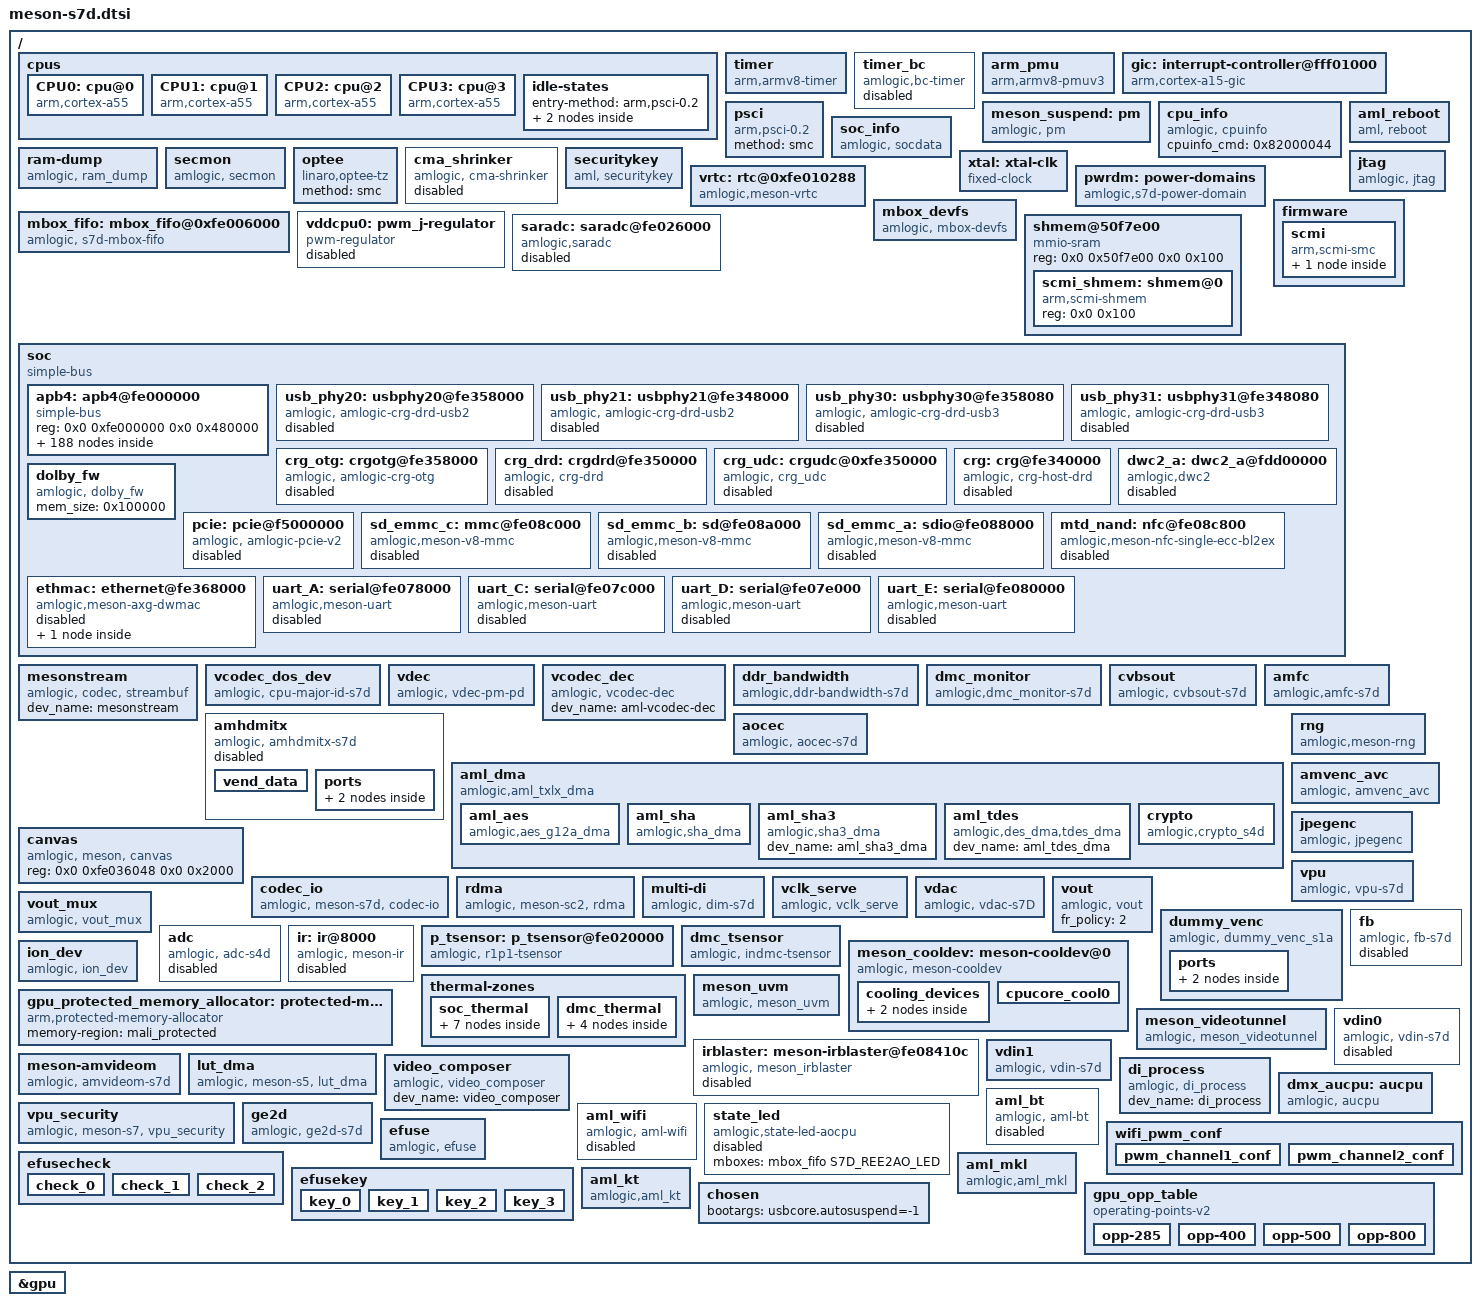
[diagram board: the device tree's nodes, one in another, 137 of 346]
// SPDX-License-Identifier: (GPL-2.0+ OR MIT)
/*
 * Copyright (c) 2019 Amlogic, Inc. All rights reserved.
 */

#include <dt-bindings/clock/s7d-clkc.h>
#include <dt-bindings/clock/s7d-scmi-clkc.h>
#include <dt-bindings/clock/g12a-aoclkc.h>
#include <dt-bindings/interrupt-controller/irq.h>
#include <dt-bindings/interrupt-controller/arm-gic.h>
#include <dt-bindings/power/s7d-pd.h>
#include <dt-bindings/gpio/gpio.h>
#include <dt-bindings/gpio/meson-s7d-gpio.h>
#include <dt-bindings/reset/amlogic,meson-s7d-reset.h>
#include <dt-bindings/pwm/pwm.h>
#include <dt-bindings/pwm/meson.h>
#include <dt-bindings/input/input.h>
#include <dt-bindings/input/meson_ir.h>
#include <dt-bindings/mailbox/amlogic,mbox.h>
#include <dt-bindings/mailbox/s7d-mbox.h>
#include <dt-bindings/iio/adc/amlogic-saradc.h>
#include "meson-ir-map.dtsi"
#include "meson-valhall.dtsi"

/ {
	cpus:cpus {
		#address-cells = <2>;
		#size-cells = <0>;

		CPU0:cpu@0 {
			device_type = "cpu";
			compatible = "arm,cortex-a55","arm,armv8";
			reg = <0x0 0x0>;
			enable-method = "psci";
			cpu-idle-states = <&CPU_SLEEP_0 &SYSTEM_SLEEP_0>;
			dynamic-power-coefficient = <230>;
			#cooling-cells = <2>;
		};

		CPU1:cpu@1 {
			device_type = "cpu";
			compatible = "arm,cortex-a55","arm,armv8";
			reg = <0x0 0x100>;
			enable-method = "psci";
			cpu-idle-states = <&CPU_SLEEP_0 &SYSTEM_SLEEP_0>;
			dynamic-power-coefficient = <230>;
			#cooling-cells = <2>;
		};

		CPU2:cpu@2 {
			device_type = "cpu";
			compatible = "arm,cortex-a55","arm,armv8";
			reg = <0x0 0x200>;
			enable-method = "psci";
			cpu-idle-states = <&CPU_SLEEP_0 &SYSTEM_SLEEP_0>;
			dynamic-power-coefficient = <230>;
			#cooling-cells = <2>;
		};

		CPU3:cpu@3 {
			device_type = "cpu";
			compatible = "arm,cortex-a55","arm,armv8";
			reg = <0x0 0x300>;
			enable-method = "psci";
			cpu-idle-states = <&CPU_SLEEP_0 &SYSTEM_SLEEP_0>;
			dynamic-power-coefficient = <230>;
			#cooling-cells = <2>;
		};

		idle-states {
			entry-method = "arm,psci-0.2";
			CPU_SLEEP_0: cpu-sleep-0 {
					compatible = "arm,idle-state";
					arm,psci-suspend-param = <0x0010000>;
					local-timer-stop;
					entry-latency-us = <1444>;
					exit-latency-us = <675>;
					min-residency-us = <2638>;
			};
			SYSTEM_SLEEP_0: system-sleep-0 {
					compatible = "arm,idle-state";
					arm,psci-suspend-param = <0x0000000>;
					entry-latency-us = <0x3fffffff>;
					exit-latency-us = <0x40000000>;
					min-residency-us = <0xffffffff>;
			};
		};
	};

	timer {
		compatible = "arm,armv8-timer";
		interrupts = <GIC_PPI 13 0xff08>,
				<GIC_PPI 14 0xff08>,
				<GIC_PPI 11 0xff08>,
				<GIC_PPI 10 0xff08>;
	};

	timer_bc {
		compatible = "amlogic,bc-timer";
		status = "disabled";
		reg= <0x0 0xfe0100D8 0x0 0x4 0x0 0xfe0100DC 0x0 0x4>;
		timer_name = "Meson TimerD";
		clockevent-rating=<300>;
		clockevent-shift=<20>;
		clockevent-features=<0x23>;
		interrupts = <0 3 1>;
		bit_enable=<7>;
		bit_mode=<6>;
		bit_resolution=<0>;
		resolution_1us=<1>;
		min_delta_ns=<10>;
	};

	arm_pmu {
		compatible = "arm,armv8-pmuv3";
		private-interrupts;
		/* clusterb-enabled; */
		interrupts = <GIC_SPI 235 IRQ_TYPE_LEVEL_HIGH>,
				<GIC_SPI 236 IRQ_TYPE_LEVEL_HIGH>,
				<GIC_SPI 237 IRQ_TYPE_LEVEL_HIGH>,
				<GIC_SPI 238 IRQ_TYPE_LEVEL_HIGH>;
	};

	gic: interrupt-controller@fff01000 {
		compatible = "arm,cortex-a15-gic", "arm,cortex-a9-gic";
		#interrupt-cells = <3>;
		#address-cells = <0>;
		interrupt-controller;
		reg = <0x0 0xfff01000 0 0x1000>,
		      <0x0 0xfff02000 0 0x0100>;
		interrupts = <GIC_PPI 9 0xf04>;
	};

	psci {
		compatible = "arm,psci-0.2";
		method = "smc";
	};

	meson_suspend:pm {
		compatible = "amlogic, pm";
		status = "okay";
		device_name = "aml_pm";
		extend_resume_reason;
		reg = <0x0 0xfe010288 0x0 0x4>, /*SYSCTRL_STATUS_REG2*/
			<0x0 0xfe0102dc 0x0 0x4>; /*SYSCTRL_STICKY_REG7*/
	};

	cpu_info {
		compatible = "amlogic, cpuinfo";
		status = "okay";
		cpuinfo_cmd = <0x82000044>;
	};

	soc_info {
		compatible = "amlogic, socdata";
		reg =	<0x0 0xfe010000 0x0 0xc>,
			<0x0 0xfe010180 0x0 0x4>;
		read_nocsdata_cmd =<0x82000039>;
		write_nocsdata_cmd=<0x82000038>;
		auth_reg_ops_cmd=<0x820000f0>;
	};

	aml_reboot {
		compatible = "aml, reboot";
		sys_reset = <0x84000009>;
		sys_poweroff = <0x84000008>;
		dis_nb_cpus_in_shutdown;
		extend_reboot_reason; /* Support up to 128 reboot reasons*/
		reg = <0x0 0xfe01037c 0x0 0x4>; /* SEC_AO_SEC_SD_CFG15 */
		status = "okay";
	};

	ram-dump {
		compatible = "amlogic, ram_dump";
		status = "okay";
		reg = <0x0 0xFE0102D8 0x0 4>;
		reg-names = "SYSCTRL_STICKY_REG6";
		store_device = "data";
	};

	secmon:secmon {
		compatible = "amlogic, secmon";
		memory-region = <&secmon_reserved>;
		in_base_func = <0x82000020>;
		out_base_func = <0x82000021>;
		inout_size_func = <0x8200002a>;
		reserve_mem_size = <0x03300000>;
	};

	optee {
		compatible = "linaro,optee-tz";
		method = "smc";
	};

	cma_shrinker: cma_shrinker {
		compatible = "amlogic, cma-shrinker";
		status = "disabled";
		adj  = <0 100 200 250 900 950>;
		free = <8192 12288 16384 24576 28672 32768>;
	};

	securitykey {
		compatible = "aml, securitykey";
		storage_query = <0x82000060>;
		storage_read = <0x82000061>;
		storage_write = <0x82000062>;
		storage_tell = <0x82000063>;
		storage_verify = <0x82000064>;
		storage_status = <0x82000065>;
		storage_list = <0x82000067>;
		storage_remove = <0x82000068>;
		storage_in_func = <0x82000023>;
		storage_out_func = <0x82000024>;
		storage_block_func = <0x82000025>;
		storage_size_func = <0x82000027>;
		storage_set_enctype = <0x8200006A>;
		storage_get_enctype = <0x8200006B>;
		storage_version = <0x8200006C>;
	};

	xtal: xtal-clk {
		compatible = "fixed-clock";
		clock-frequency = <24000000>;
		clock-output-names = "xtal";
		#clock-cells = <0>;
	};

	vrtc: rtc@0xfe010288 {
		compatible = "amlogic,meson-vrtc";
		reg = <0x0 0xfe010288 0x0 0x4>;
		status = "okay";
		mboxes = <&mbox_fifo S7D_REE2AO_VRTC>;
	};

	pwrdm: power-domains {
		compatible = "amlogic,s7d-power-domain";
		#power-domain-cells = <1>;
		status = "okay";
	};

	jtag {
		compatible = "amlogic, jtag";
		status = "okay";
		select = "disable"; /* disable/jtag_a/jtag_b */
		pinctrl-names="jtag_a_pins", "jtag_b_pins";
		pinctrl-0=<&jtag_a_pins>;
		pinctrl-1=<&jtag_b_pins>;
	};

	mbox_fifo: mbox_fifo@0xfe006000 {
		status = "okay";
		compatible = "amlogic, s7d-mbox-fifo";
		reg = <0x0 0xfe006000 0x0 0x800>,  /* mbox wr fifo */
		      <0x0 0xfe006800 0x0 0x800>,  /* mbox rd fifo */
		      <0x0 0xfe0070c0 0x0 0x40>,   /* mbox set reg */
		      <0x0 0xfe007100 0x0 0x40>,   /* mbox clr reg */
		      <0x0 0xfe007140 0x0 0x40>,   /* mbox sts reg */
		      <0x0 0xfe007020 0x0 0x40>;   /* mbox irqctrl reg */
		interrupts = <GIC_SPI 248 IRQ_TYPE_EDGE_RISING>;   /* mbox top irq */
		mbox-irqctlr = <0>;
		mbox-nums = <S7D_MBOX_NUMS>;
		mboxids = <S7D_MBOX_AO2REE>,
			  <S7D_MBOX_REE2AO>;
		aocpu_sts_mboxid = <S7D_MBOX_AO2TEE>;
		ree2aocpu_mboxid = <S7D_MBOX_REE2AO>;
		#mbox-cells = <1>;
	};

	mbox_devfs {
		status = "okay";
		compatible = "amlogic, mbox-devfs";
		mbox-nums = <1>;
		mbox-names = "ree2aocpu";
		mboxes = <&mbox_fifo S7D_REE2AO_DEV>;
		mbox-dests = <MAILBOX_AOCPU>;
	};

	vddcpu0: pwm_j-regulator {
		compatible = "pwm-regulator";
		pwms = <&pwm_j MESON_PWM_0 1000 0>;
		regulator-name = "vddcpu0";
		regulator-min-microvolt = <679000>;
		regulator-max-microvolt = <979000>;
		regulator-always-on;
		max-duty-cycle = <1000>;
		amlogic,vsel-step = <3>;
		amlogic,usleep-time = <200>;
		/* Voltage Duty-Cycle */
		voltage-table = <979000 0>,
				<969000 3>,
				<959000 7>,
				<949000 10>,
				<939000 13>,
				<929000 17>,
				<919000 20>,
				<909000 23>,
				<899000 26>,
				<889000 30>,
				<879000 33>,
				<869000 36>,
				<859000 40>,
				<849000 43>,
				<839000 46>,
				<829000 50>,
				<819000 54>,
				<809000 57>,
				<799000 60>,
				<789000 64>,
				<779000 67>,
				<769000 70>,
				<759000 74>,
				<749000 77>,
				<739000 80>,
				<729000 84>,
				<719000 87>,
				<709000 90>,
				<699000 93>,
				<689000 97>,
				<679000 100>;
		status = "disabled";
	};

	saradc: saradc@fe026000 {
		compatible = "amlogic,saradc";
		reg = <0x00 0xfe026000 0x00 0x84>;
		interrupts = <GIC_SPI 181 IRQ_TYPE_EDGE_RISING>;
		clock-names = "src", "core", "gate", "mux";
		clocks = <&xtal>,
			 <&clkc CLKID_SYS_SAR_ADC>,
			 <&clkc CLKID_SAR_ADC>,
			 <&clkc CLKID_SAR_ADC_SEL>;
		#io-channel-cells = <1>;
		amlogic,clock-frequency = <3000000>;
		amlogic,test-channel = <7>;
		amlogic,fifo-data-width = <16>;
		status = "disabled";
	};

	shmem@50f7e00 {
		compatible = "mmio-sram";
		reg = <0x0 0x50f7e00 0x0 0x100>;
		#address-cells = <1>;
		#size-cells = <1>;
		ranges = <0 0x0 0x50f7e00 0x100>;

		scmi_shmem: shmem@0 {
			compatible = "arm,scmi-shmem";
			reg = <0x0 0x100>;
		};
	};

	firmware {
		scmi: scmi {
			compatible = "arm,scmi-smc";
			arm,smc-id = <0x820000C1>;
			shmem = <&scmi_shmem>;
			#address-cells = <1>;
			#size-cells = <0>;

			scmi_clk: protocol@14 {
				reg = <0x14>;
				#clock-cells = <1>;
			};
		};
	};

	soc {
		compatible = "simple-bus";
		#address-cells = <2>;
		#size-cells = <2>;
		ranges;

		apb4: apb4@fe000000 {
			compatible = "simple-bus";
			reg = <0x0 0xfe000000 0x0 0x480000>;
			#address-cells = <2>;
			#size-cells = <2>;
			ranges = <0x0 0x0 0x0 0xfe000000 0x0 0x480000>;

			clkc: clock-controller {
				compatible = "amlogic,s7d-clkc";
				#clock-cells = <1>;
				reg = <0x0 0x0 0x0 0x49c>,
				      <0x0 0x8000 0x0 0x384>;
				reg-names = "basic", "pll";
				clocks = <&xtal>,
					 <&scmi_clk CLKID_SCMI_GP0_PLL_SRC>,
					 <&scmi_clk CLKID_SCMI_HIFI0_PLL_SRC>,
					 <&scmi_clk CLKID_SCMI_ETH_HIFI1_PLL_SRC>,
					 <&scmi_clk CLKID_SCMI_SYS_CLK>,
					 <&scmi_clk CLKID_SCMI_AXI_CLK>,
					 <&scmi_clk CLKID_SCMI_FIXED_PLL>,
					 <&scmi_clk CLKID_SCMI_GP1_PLL>;
				clock-names = "xtal",
					      "gp0_pll_src",
					      "hifi0_pll_src",
					      "hifi1_pll_src",
					      "sys_clk",
					      "axi_clk",
					      "fixed_pll",
					      "gp1_pll";
				status = "okay";
			};

			meson_clk_msr@48000 {
				compatible = "amlogic,meson-s7d-clk-measure";
				reg = <0x0 0x48000 0x0 0x1c>;
			};

			watchdog@2100 {
				compatible = "amlogic,meson-sc2-wdt";
				status = "okay";
				/* 0:userspace, 1:kernel */
				amlogic,feed_watchdog_mode = <1>;
				reg = <0x0 0x2100 0x0 0x10>;
				clocks = <&xtal>;
			};

			periphs_pinctrl: pinctrl@4000 {
				compatible = "amlogic,meson-s7d-periphs-pinctrl";
				#address-cells = <2>;
				#size-cells = <2>;
				ranges;

				gpio: bank@4000 {
					reg = <0x0 0x4000 0x0 0x004c>,
					      <0x0 0x40c0 0x0 0x02cc>;
					reg-names = "mux", "gpio";
					gpio-controller;
					#gpio-cells = <2>;
					gpio-ranges = <&periphs_pinctrl 0 0 84>;
				};
			};

			gpio_intc: interrupt-controller@4080 {
				compatible = "amlogic,meson-s7-gpio-intc",
					     "amlogic,meson-gpio-intc";
				reg = <0x0 0x4080 0x0 0x20>;
				interrupt-controller;
				#interrupt-cells = <2>;
				amlogic,channel-interrupts =
					<10 11 12 13 14 15 16 17 18 19 20 21>;
			};

			spicc0: spi@50000 {
				compatible = "amlogic,meson-a4-spicc-v2";
				reg = <0x0 0x50000 0x0 0x38>;
				interrupts = <GIC_SPI 183 IRQ_TYPE_LEVEL_HIGH>;
				clocks = <&clkc CLKID_SYS_SPICC0>,
					 <&clkc CLKID_SPICC>;
				clock-names = "sys", "spi";
				assigned-clocks = <&clkc CLKID_SPICC>;
				assigned-clock-rates = <500000000>;
				#address-cells = <1>;
				#size-cells = <0>;
				status = "disabled";
			};

			spifc: spi@56000 {
				compatible = "amlogic,meson-spifc";
				status = "disabled";
				reg = <0x0 0x56000 0x0 0x80>;
				//clock-names = "default";
				//clocks = <&clkc CLKID_SPIFC>;
				pinctrl-names = "default";
				pinctrl-0 = <&spifc_pins>;
				#address-cells = <1>;
				#size-cells = <0>;
				spi-nor@0 {
					compatible = "jedec,spi-nor";
					status = "disabled";
					reg = <0>;
					spi-max-frequency = <16000000>;
				};
			};

			pwm_a: pwm@58000 {
				compatible = "amlogic,meson-even-pwm";
				reg = <0x0 0x58000 0x0 0x24>,
					  <0x0 0x180 0x0 0x4>;
				#pwm-cells = <3>;
				clocks = <&clkc CLKID_PWM_A_SEL>;
				clock-names = "clkin0";
				status = "disabled";
			};

			pwm_b: pwm@58200 {
				compatible = "amlogic,meson-odd-pwm";
				reg = <0x0 0x58200 0x0 0x24>,
					  <0x0 0x180 0x0 0x4>;
				#pwm-cells = <3>;
				clocks = <&clkc CLKID_PWM_B_SEL>;
				clock-names = "clkin0";
				status = "disabled";
			};

			pwm_c: pwm@58400 {
				compatible = "amlogic,meson-even-pwm";
				reg = <0x0 0x58400 0x0 0x24>,
					  <0x0 0x184 0x0 0x4>;
				#pwm-cells = <3>;
				clocks = <&clkc CLKID_PWM_C_SEL>;
				clock-names = "clkin0";
				status = "disabled";
			};

			pwm_d: pwm@58600 {
				compatible = "amlogic,meson-odd-pwm";
				reg = <0x0 0x58600 0x0 0x24>,
					  <0x0 0x184 0x0 0x4>;
				#pwm-cells = <3>;
				clocks = <&clkc CLKID_PWM_D_SEL>;
				clock-names = "clkin0";
				status = "disabled";
			};

			pwm_e: pwm@58800 {
				compatible = "amlogic,meson-even-pwm";
				reg = <0x0 0x58800 0x0 0x24>,
					  <0x0 0x188 0x0 0x4>;
				#pwm-cells = <3>;
				clocks = <&clkc CLKID_PWM_E_SEL>;
				clock-names = "clkin0";
				status = "disabled";
			};

			pwm_f: pwm@58a00 {
				compatible = "amlogic,meson-odd-pwm";
				reg = <0x0 0x58a00 0x0 0x24>,
					  <0x0 0x188 0x0 0x4>;
				#pwm-cells = <3>;
				clocks = <&clkc CLKID_PWM_F_SEL>;
				clock-names = "clkin0";
				status = "disabled";
			};

			pwm_g: pwm@58c00 {
				compatible = "amlogic,meson-even-pwm";
				reg = <0x0 0x58c00 0x0 0x24>,
					  <0x0 0x18c 0x0 0x4>;
				#pwm-cells = <3>;
				clocks = <&clkc CLKID_PWM_G_SEL>;
				clock-names = "clkin0";
				status = "disabled";
			};

			pwm_h: pwm@58e00 {
				compatible = "amlogic,meson-odd-pwm";
				reg = <0x0 0x58e00 0x0 0x24>,
					  <0x0 0x18c 0x0 0x4>;
				#pwm-cells = <3>;
				clocks = <&clkc CLKID_PWM_H_SEL>;
				clock-names = "clkin0";
				status = "disabled";
			};

			pwm_i: pwm@59000 {
				compatible = "amlogic,meson-even-pwm";
				reg = <0x0 0x59000 0x0 0x24>,
					  <0x0 0x190 0x0 0x4>;
				#pwm-cells = <3>;
				clocks = <&clkc CLKID_PWM_I_SEL>;
				clock-names = "clkin0";
				status = "disabled";
			};

			pwm_j: pwm@59200 {
				compatible = "amlogic,meson-pwm-tee";
				reg = <0x0 0x59200 0x0 0x24>;
				#pwm-cells = <3>;
				clocks = <&clkc CLKID_PWM_J>;
				clock-names = "clkin0";
				tee_id = <9>;
				status = "okay";
			};

			i2c0: i2c@66000 {
				compatible = "amlogic,meson-i2c";
				reg = <0x0 0x66000 0x0 0x48>;
				interrupts = <GIC_SPI 160 IRQ_TYPE_EDGE_RISING>;
				#address-cells = <1>;
				#size-cells = <0>;
				clocks = <&clkc CLKID_SYS_I2C_M_A>;
				status = "disabled";
			};

			i2c1: i2c@66400 {
				compatible = "amlogic,meson-i2c";
				reg = <0x0 0x66400 0x0 0x48>;
				interrupts = <GIC_SPI 161 IRQ_TYPE_EDGE_RISING>;
				#address-cells = <1>;
				#size-cells = <0>;
				clocks = <&clkc CLKID_SYS_I2C_M_B>;
				status = "disabled";
			};

			i2c2: i2c@66800 {
				compatible = "amlogic,meson-i2c";
				reg = <0x0 0x66800 0x0 0x48>;
				interrupts = <GIC_SPI 162 IRQ_TYPE_EDGE_RISING>;
				#address-cells = <1>;
				#size-cells = <0>;
				clocks = <&clkc CLKID_SYS_I2C_M_C>;
				status = "disabled";
			};

			i2c3: i2c@66c00 {
				compatible = "amlogic,meson-i2c";
				reg = <0x0 0x66c00 0x0 0x48>;
				interrupts = <GIC_SPI 163 IRQ_TYPE_EDGE_RISING>;
				#address-cells = <1>;
				#size-cells = <0>;
				clocks = <&clkc CLKID_SYS_I2C_M_D>;
				status = "disabled";
			};

			i2c4: i2c@67000 {
				compatible = "amlogic,meson-i2c";
				reg = <0x0 0x67000 0x0 0x48>;
				interrupts = <GIC_SPI 164 IRQ_TYPE_EDGE_RISING>;
				#address-cells = <1>;
				#size-cells = <0>;
				clocks = <&clkc CLKID_SYS_I2C_M_E>;
				status = "disabled";
			};

			uart_B: serial@7a000 {
				compatible = "amlogic,meson-uart";
				reg = <0x0 0x7a000 0x0 0x18>;
				interrupts = <0 169 1>;
				status = "okay";
				clocks = <&xtal>;
				clock-names = "clk_uart";
				xtal_tick_en = <2>;
				fifosize = < 64 >;
				support-sysrq = <1>;  /* 0 not support*/
			};


			eth_phy: mdio-multiplexer@360000 {
				compatible = "amlogic,g12a-mdio-mux";
				reg = <0x0 0x360000 0x0 0xa4>;

				clocks = <&clkc CLKID_SYS_ETHPHY>,
					 <&xtal>,
					 <&clkc CLKID_FCLK_CLK50M>,
					 <&clkc CLKID_ETH_RMII>;
				clock-names = "pclk", "clkin0", "clkin1","ethrmii";
				assigned-clocks = <&clkc CLKID_ETH_RMII>;
				assigned-clock-rates = <50000000>;
				mdio-parent-bus = <&mdio0>;
				#address-cells = <1>;
				#size-cells = <0>;
				enet_type = <5>;
				phy_pll_mode = <3>;
				phy_mode = <5>;
				tx_amp_src = <0xFE010330>;
				led_setting = <0x42>;

				ext_mdio: mdio@0 {
					reg = <0>;
					#address-cells = <1>;
					#size-cells = <0>;
				};

				int_mdio: mdio@1 {
					reg = <1>;
					#address-cells = <1>;
					#size-cells = <0>;

					internal_ephy: ethernet_phy@8 {
						compatible = "ethernet-phy-id0180.3301",
							     "ethernet-phy-ieee802.3-c22";
						interrupts = <GIC_SPI 75 IRQ_TYPE_LEVEL_HIGH>;
						reg = <8>;
						max-speed = <100>;
					};
				};
			};

			reset: reset-controller@2000 {
				compatible = "amlogic,meson-sc2-reset";
				reg = <0x0 0x2000 0x0 0x98>;
				#reset-cells = <1>;
			};
		};

		usb_phy20: usbphy20@fe358000 {
			compatible = "amlogic, amlogic-crg-drd-usb2";
			status = "disable";
			reg = <0x0 0xfe358000 0x0 0x10 /* phy_base */
					0x0 0xfe002000 0x0 0x100 /* reset_base */
					0x0 0xfe35c000 0x0 0x60>; /* phy_cfg_base(s) */
			pll-setting-1 = <0x244a0030>;
			pll-setting-2 = <0x03200022>;
			pll-setting-4 = <0x7e18>;
			pll-setting-5 = <0x7>;
			//dis-thred-enhance = <0x2>;
			pll-version = <3>;
			phy0-reset-level-bit = <8>;
			usb-reset-bit = <5>;
			reset-level = <0x40>;
			usb-phy-trim-reg = <0xfe010330>;
			phy-id = <0>;
			clocks = <&clkc CLKID_SYS_USB>;
			clock-names = "crg_general";
		};

		usb_phy21: usbphy21@fe348000 {
			compatible = "amlogic, amlogic-crg-drd-usb2";
			status = "disable";
			reg = <0x0 0xfe348000 0x0 0x10 /* phy_base */
					0x0 0xfe002000 0x0 0x100 /* reset_base */
					0x0 0xfe34c000 0x0 0x60>; /* phy_cfg_base(s) */
			pll-setting-1 = <0x244a0030>;
			pll-setting-2 = <0x03200022>;
			pll-setting-4 = <0x7e18>;
			pll-setting-5 = <0x7>;
			//dis-thred-enhance = <0x2>;
			pll-version = <3>;
			phy0-reset-level-bit = <9>;
			usb-reset-bit = <4>;
			reset-level = <0x40>;
			usb-phy-trim-reg = <0xfe010330>;
			phy-id = <1>;
			clocks = <&clkc CLKID_SYS_USB>;
			clock-names = "crg_general";
		};

		usb_phy30: usbphy30@fe358080 {
			compatible = "amlogic, amlogic-crg-drd-usb3";
			status = "disable";
			reg = <0x0 0xfe358080 0x0 0x0>; /* phy3 base */
			phy1-reg = <0xfe358080>; /* phy3 cfg base */
			phy1-reg-size = <0x18>;
			reset-reg = <0xfe002000>;
			reset-reg-size = <0x100>;
			phy-id = <0>;
			portnum = <0>;
		};

		usb_phy31: usbphy31@fe348080 {
			compatible = "amlogic, amlogic-crg-drd-usb3";
			status = "disable";
			reg = <0x0 0xfe348080 0x0 0x0>; /* phy3 base */
			phy1-reg = <0xfe348080>; /* phy3 cfg base */
			phy1-reg-size = <0x18>;
			reset-reg = <0xfe002000>;
			reset-reg-size = <0x100>;
			phy-id = <1>;
			portnum = <0>;
		};

		crg_otg: crgotg@fe358000 {
			compatible = "amlogic, amlogic-crg-otg";
			status = "disabled";
			usb2-phy-reg = <0xfe358000>;
			usb2-phy-reg-size = <0x80>;
			usb3-phy-reg = <0xfe358080>;
			usb3-phy-reg-size = <0x20>;
			interrupts = <0 129 IRQ_TYPE_EDGE_RISING>;
			udc-name = "0xfe350000.crgudc";
		};

		crg_drd: crgdrd@fe350000 {
			compatible = "amlogic, crg-drd";
			status = "disabled";
			reg = <0x0 0xfe350000 0x0 0x8000>;
			interrupts = <GIC_SPI 131 IRQ_TYPE_EDGE_RISING>;
			usb-phy = <&usb_phy20>, <&usb_phy30>;
			clocks = <&clkc CLKID_SYS_USB>;
			clock-names = "crg_general";
		};

		crg_udc: crgudc@0xfe350000 {
			compatible = "amlogic, crg_udc";
			status = "disable";
			controller-type = <1>; /* 1: aml phy 4: m31 phy */
			reg = <0x0 0xfe350000 0x0 0x8000>;
			interrupts = <0 131 IRQ_TYPE_EDGE_RISING>;
			port-speed = <3>; /* 0~3: unknown, low, full, high */
			phy-reg = <0xfe358000>; /* phy2 base*/
			phy-reg-size = <0x10>;
			clocks = <&clkc CLKID_SYS_USB>;
			clock-names = "usb_general";
			phy-id = <0>;
			version = <1>; /* 1: forbid vbus detect */
		};

		crg: crg@fe340000 {
			compatible = "amlogic, crg-host-drd";
			status = "disable";
			reg = <0x0 0xfe340000 0x0 0x8000>;
			interrupts = <0 130 IRQ_TYPE_EDGE_RISING>;
			usb-phy = <&usb_phy21>, <&usb_phy31>;
			clocks = <&clkc CLKID_SYS_USB>;
			clock-names = "crg_general";
		};

		dwc2_a: dwc2_a@fdd00000 {
			compatible = "amlogic,dwc2";
			status = "disable";
			device_name = "dwc2_a";
			reg = <0x0 0xfdd00000 0x0 0x100000>;
			interrupts = <0 131 4>;
			pl-periph-id = <0>; /** lm name */
			clock-src = "usb0"; /** clock src */
			port-id = <0>;  /** ref to mach/usb.h */
			port-type = <2>;        /** 0: otg, 1: host, 2: slave */
			port-speed = <0>; /** 0: default, high, 1: full */
			port-config = <0>; /** 0: default */
			/*0:default,1:single,2:incr,3:incr4,4:incr8,5:incr16,6:disable*/
			port-dma = <0>;
			port-id-mode = <0>; /** 0: hardware, 1: sw_host, 2: sw_slave*/
			usb-fifo = <728>;
			cpu-type = "v2";
			phy-reg = <0xfe03a000>;
			phy-reg-size = <0xa0>;
			/** phy-interface: 0x0: amlogic phy, 0x1: synopsys phy **/
			phy-interface = <0x2>;
			//clocks = <&clkc CLKID_USB
			//			&clkc CLKID_USB1_TO_DDR>;
			//clock-names = "usb_general",
			//			"usb1";
		};

		dolby_fw: dolby_fw {
			compatible = "amlogic, dolby_fw";
			mem_size = <0x100000>;
			status = "okay";
		};

		pcie: pcie@f5000000 {
			compatible = "amlogic, amlogic-pcie-v2", "snps,dw-pcie";
			reg = <0x0 0xf5000000 0x0 0x400000
				0x0 0xfe02c000 0x0 0x2000
				0x0 0xf5400000 0x0 0x200000
				0x0 0xfe02a000 0x0 0x2000
				0x0 0xfe002044 0x0 0x10>;
			reg-names = "elbi", "cfg", "config", "phy", "reset";
			interrupts = <GIC_SPI 141 IRQ_TYPE_EDGE_RISING>;
			#interrupt-cells = <1>;
			bus-range = <0x0 0xff>;
			#address-cells = <3>;
			#size-cells = <2>;
			interrupt-map-mask = <0 0 0 0>;
			interrupt-map = <0 0 0 0 &gic GIC_SPI 143 IRQ_TYPE_EDGE_RISING>;
			device_type = "pci";
			ranges = <0x81000000 0 0 0 0xf5600000 0x0 0x100000
				/* downstream I/O */
				0x82000000 0 0xf5700000 0x0 0xf5700000 0 0x1900000>;
				/* non-prefetchable memory */
			num-lanes = <1>;
			pcie-num = <1>;

			//clocks = <&clkc CLKID_PCIE_PLL
			//	&clkc CLKID_PCIE
			//	&clkc CLKID_PCIE_PHY>;
			//clock-names = "pcie_refpll",
			//		"pcie",
			//		"pcie_phy";
			/*reset-gpio-type 0:Shared pad(no reset)1:OD pad2:Normal pad*/
			gpio-type = <2>;
			pcie-apb-rst-bit = <14>;
			pcie-phy-rst-bit = <13>;
			pcie-ctrl-a-rst-bit = <12>;
			pwr-ctl = <0>;
//			power-domains = <&pwrdm PDID_SC2_PCIE>;
			pcie-ctrl-sleep-shift = <15>;
			pcie-hhi-mem-pd-shift = <26>;
			pcie-hhi-mem-pd-mask = <0xf>;
			pcie-ctrl-iso-shift = <15>;
			status = "disabled";
		};

		sd_emmc_c: mmc@fe08c000 {
			compatible = "amlogic,meson-v8-mmc";
			reg = <0x0 0xfe08c000 0x0 0x800>,
				<0x0 0xfe000168 0x0 0x4>,
				<0x0 0xfe004000 0x0 0x4>;
			interrupts = <GIC_SPI 178 IRQ_TYPE_EDGE_RISING>;
			status = "disabled";
			clocks = <&clkc CLKID_SYS_SD_EMMC_C>,
				<&clkc CLKID_SD_EMMC_C_SEL>,
				 <&clkc CLKID_SD_EMMC_C>,
				 <&xtal>,
				 <&clkc CLKID_GP0_PLL>,
				 <&clkc CLKID_GP0_PLL>;
			clock-names = "core", "mux0", "mux1",
					"clkin0", "clkin1", "clkin2";
			no-sdio;
			no-sd;
			card_type = <1>;
			ignore_desc_busy;
			mmc_debug_flag;
			src_clk_rate = <1152000000>;
			tx_delay = <14>;
			cap-mmc-crypto;
		//	nwr_cnt = <0>;
		//	resets = <&reset RESET_SD_EMMC_C>;
		};

		sd_emmc_b: sd@fe08a000 {
			compatible = "amlogic,meson-v8-mmc";
			reg = <0x0 0xfe08a000 0x0 0x800>,
				<0x0 0xfe00016c 0x0 0x4>,
				<0x0 0xfe004024 0x0 0x4>;
			interrupts = <GIC_SPI 177 IRQ_TYPE_EDGE_RISING>;
			status = "disabled";
			clocks = <&clkc CLKID_SYS_SD_EMMC_B>,
				<&clkc CLKID_SD_EMMC_B_SEL>,
				 <&clkc CLKID_SD_EMMC_B>,
				 <&xtal>,
				 <&clkc CLKID_FCLK_DIV2>;
			clock-names = "core", "mux0", "mux1",
					"clkin0", "clkin1";
			card_type = <5>;
			mmc_debug_flag;
			no-mmc;
			no-sdio;
			//resets = <&reset RESET_SD_EMMC_B>;
		};

		sd_emmc_a: sdio@fe088000 {
			compatible = "amlogic,meson-v8-mmc";
			reg = <0x0 0xfe088000 0x0 0x800>,
				<0x0 0xfe00016c 0x0 0x4>,
				<0x0 0xfe00400c 0x0 0x4>;
			interrupts = <GIC_SPI 176 IRQ_TYPE_LEVEL_HIGH>;
			status = "disabled";
			clocks = <&clkc CLKID_SYS_SD_EMMC_A>,
				<&clkc CLKID_SD_EMMC_A_SEL>,
				 <&clkc CLKID_SD_EMMC_A>,
				 <&xtal>,
				 <&clkc CLKID_FCLK_DIV2>;
			clock-names = "core", "mux0", "mux1",
					"clkin0", "clkin1";
			card_type = <3>;
			mmc_debug_flag;
			cap-sdio-irq;
			keep-power-in-suspend;
			use_intf3_tuning;
			no-mmc;
			no-sd;
			//resets = <&reset RESET_SD_EMMC_A>;
		};

		mtd_nand: nfc@fe08c800 {
			compatible = "amlogic,meson-nfc-single-ecc-bl2ex";
			status = "disabled";
			reg = <0x0 0xfe08c800 0x0 0x200>;
			interrupts = <GIC_SPI 175 IRQ_TYPE_EDGE_RISING>;

			//clocks = <&clkc CLKID_NAND>,
			//		 <&clkc CLKID_FCLK_DIV2>;
			//clock-names = "gate", "fdiv2pll";
			nand_clk_ctrl = <0xfe08c000>;
		};

		ethmac: ethernet@fe368000 {
			compatible = "amlogic,meson-axg-dwmac",
				     "snps,dwmac-4.00";
			reg = <0x0 0xfe368000 0x0 0x12ec>,
			      <0x0 0xfe364000 0x0 0x8>;
			interrupts = <GIC_SPI 74 IRQ_TYPE_LEVEL_HIGH>;
			interrupt-names = "macirq";
			clocks = <&clkc CLKID_SYS_ETHPHY>,
				 <&clkc CLKID_FCLK_DIV2>,
				 <&clkc CLKID_FCLK_CLK50M>;
			clock-names = "stmmaceth", "clkin0", "clkin1";
			rx-fifo-depth = <4096>;
			tx-fifo-depth = <2048>;
			mboxes = <&mbox_fifo S7D_REE2AO_ETH>;
			status = "disabled";
			analog_version = <1>;
			mdio0: mdio {
				#address-cells = <1>;
				#size-cells = <0>;
				compatible = "snps,dwmac-mdio";
			};
		};

		uart_A: serial@fe078000 {
			compatible = "amlogic,meson-uart";
			reg = <0x0 0xfe078000 0x0 0x18>;
			interrupts = <0 168 1>;
			status = "disabled";
			clocks = <&xtal
					&clkc CLKID_SYS_UART_A>;
			clock-names = "clk_uart",
					"clk_gate";
			fifosize = < 64 >;
			pinctrl-names = "default";
			pinctrl-0 = <&a_uart_pins>;
			uart_for_bt = <1>;
		};

		uart_C: serial@fe07c000 {
			compatible = "amlogic,meson-uart";
			reg = <0x0 0xfe07c000 0x0 0x18>;
			interrupts = <0 170 1>;
			status = "disabled";
			clocks = <&xtal
					&clkc CLKID_SYS_UART_C>;
			clock-names = "clk_uart",
					"clk_gate";
			fifosize = < 64 >;
			pinctrl-names = "default";
			pinctrl-0 = <&c_uart_pins>;
		};

		uart_D: serial@fe07e000 {
			compatible = "amlogic,meson-uart";
			status = "disabled";
			reg = <0x0 0xfe07e000 0x0 0x18>;
			interrupts = <0 171 1>;
			clocks = <&xtal
					&clkc CLKID_SYS_UART_D>;
			clock-names = "clk_uart",
					"clk_gate";
			fifosize = < 64 >;
			pinctrl-names = "default";
			pinctrl-0 = <&d_uart_pins1>;
		};

		uart_E: serial@fe080000 {
			compatible = "amlogic,meson-uart";
			status = "disabled";
			reg = <0x0 0xfe080000 0x0 0x18>;
			interrupts = <0 172 1>;
			clocks = <&xtal
					&clkc CLKID_SYS_UART_E>;
			clock-names = "clk_uart",
					"clk_gate";
			fifosize = < 64 >;
			pinctrl-names = "default";
			pinctrl-0 = <&e_uart_pins1>;
		};
	};

	mesonstream {
		compatible = "amlogic, codec, streambuf";
		dev_name = "mesonstream";
		status = "okay";
	};

	vcodec_dos_dev: vcodec_dos_dev {
		compatible = "amlogic, cpu-major-id-s7d";
		dev_name = "vcodec_dos_dev";
		status = "okay";
		reg = <0x0 0xfe320000 0x0 0x10000>,
			<0x0 0xfe036000 0x0 0x2000>;
		reg-names = "dosbus",
			"dmcbus";
		clocks = <&clkc CLKID_SYS_DOS
			&clkc CLKID_VDEC
			&clkc CLKID_HCODEC
			&clkc CLKID_HEVCF>;
		clock-names = "vdec",
			"clk_vdec_mux",
			"clk_hcodec_mux",
			"clk_hevcf_mux";
		assigned-clock-parents = <&clkc CLKID_VDEC_0>,
			<&clkc CLKID_HEVCF_0>;
		assigned-clocks = <&clkc CLKID_VDEC>,
			<&clkc CLKID_HEVCF>;
	};

	vdec {
		compatible = "amlogic, vdec-pm-pd";
		dev_name = "vdec.0";
		status = "okay";
		interrupts = <0 3 1
			0 23 1
			0 32 1
			0 91 1
			0 92 1
			0 93 1
			0 72 1>;
		interrupt-names = "vsync",
			"demux",
			"parser",
			"mailbox_0",
			"mailbox_1",
			"mailbox_2",
			"parser_b";
		power-domains = <&pwrdm PDID_S7D_DOS_VDEC>,
			<&pwrdm PDID_S7D_DOS_HEVC>,
			<&pwrdm PDID_S7D_DOS_HCODEC>;
		power-domain-names = "pwrc-vdec",
			"pwrc-hevc",
			"pwrc-hcodec";
	};

	vcodec_dec {
		compatible = "amlogic, vcodec-dec";
		dev_name = "aml-vcodec-dec";
		status = "okay";
	};

	ddr_bandwidth {
		compatible = "amlogic,ddr-bandwidth-s7d";
		status = "okay";
		reg = <0x0 0xfe036000 0x0 0x400
			0x0 0xfe0368a8 0x0 0x4>;
		interrupts = <0 78 IRQ_TYPE_EDGE_RISING>;
		interrupt-names = "ddr_bandwidth";
	};

	dmc_monitor {
		compatible = "amlogic,dmc_monitor-s7d";
		status = "okay";
		reg = <0x0 0xfe036000 0x0 0x400>;
		reg_base = <0xfe036000>;
		interrupts = <0 62 IRQ_TYPE_LEVEL_HIGH>;
	};

	cvbsout: cvbsout {
		compatible = "amlogic, cvbsout-s7d";
		status = "okay";

		/* clk path */
		/* 0:vid_pll vid2_clk */
		/* 1:gp0_pll vid2_clk */
		/* 2:vid_pll vid1_clk */
		/* 3:gp0_pll vid1_clk */
		clk_path = <0>;

		/* performance: reg_address, reg_value */
		/* s4 */
		performance_pal = <0x1bf0  0x9 /* default Matrx625 CTCC value*/
			0x1b12  0x80c0
			0x1b05  0xf7
			0x1b56  0x333
			0x1c59  0xf25c
			0xffff  0x0>; /* ending flag */
		performance = <0x1bf0  0x9 /* ccitt033 SVA value */
			0x1b12  0x8040
			0x1b05  0xfd
			0x1b56  0x333
			0x1c59  0xf654
			0xffff  0x0>; /* ending flag */
		performance_ntsc = <0x1bf0  0x9
			0x1b12  0x8020
			0x1b03  0x0
			0x1b04  0x0
			0x1b05  0x0
			0x1b06  0x0
			0x1b56  0x333
			0x1c59  0xf850
			0xffff  0x0>; /* ending flag */
	};

	amfc {
		compatible = "amlogic,amfc-s7d";
		status = "okay";
		/* registers and clk */
		reg = <0x0 0xfe024000 0x0 0x200
		       0x0 0xfe000000 0x0 0x400>;
		interrupts = <0 185 IRQ_TYPE_EDGE_RISING
			      0 186 IRQ_TYPE_EDGE_RISING>;
		interrupt-names = "amfc0", "amfc1";
	};

	amhdmitx: amhdmitx{
		compatible = "amlogic, amhdmitx-s7d";
		dev_name = "amhdmitx";
		status = "disabled";
		//power-domains = <&pwrdm PDID_T7_VI_CLK2>;
		vend-data = <&vend_data>;
		pinctrl-names="hdmitx_hpd", "hdmitx_ddc";
		pinctrl-0=<&hdmitx_hpd>;
		pinctrl-1=<&hdmitx_ddc>;
		hdmitx-gpios-hpd = <&gpio GPIOH_2 0>;
		hdmitx-gpios-scl = <&gpio GPIOH_1 0>;
		hdmitx-gpios-sda = <&gpio GPIOH_0 0>;
		interrupts = <0 204 4
			0 197 1>;
		interrupt-names = "hdmitx_hpd", "vrr_vsync";
		max_refreshrate = <120>; /* the max freshrate of S7D is upto 120hz */
		reg =	<0x0 0xff000000 0x0 0x40000>,
			<0x0 0xfe310000 0x0 0x10000>,
			<0x0 0xfe300000 0x0 0x10000>,
			<0x0 0xfe010000 0x0 0x2000>,
			<0x0 0xfe00c000 0x0 0x2000>,
			<0x0 0xfe008000 0x0 0x2000>,
			<0x0 0xfe002000 0x0 0x2000>,
			<0x0 0xfe000000 0x0 0x2000>,
			<0x0 0xfe004000 0x0 0x200>;
		reg-names = "vpu",
			    "hdmitxcor",
			    "hdmitxtop",
			    "sysctrl",
			    "pwrctrl",
			    "anactrl",
			    "resetctrl",
			    "clkctrl",
			    "padctrl";

		vend_data: vend_data{ /* Should modified by Customer */
			vendor_name = "Amlogic"; /* Max Chars: 8 */
			product_desc = "MBox Meson Ref"; /* Max Chars: 16 */
			/* standards.ieee.org/develop/regauth/oui/oui.txt */
			vendor_id = <0x000000>;
		};

		ports {
			port {
				#address-cells = <1>;
				#size-cells = <0>;
				hdmitx_to_drm: endpoint@0 {
					reg = <0>;
					remote-endpoint = <0>;
				};
			};
		};
	};

	aocec: aocec {
		compatible = "amlogic, aocec-s7d";
		dev_name = "aocec";
		status = "okay";
		vendor_name = "Amlogic"; /* Max Chars: 8     */
		/* Refer to the following URL at:
		 * http://standards.ieee.org/develop/regauth/oui/oui.txt
		 */
		vendor_id = <0xffffff>;
		product_desc = "S7D"; /* Max Chars: 16    */
		cec_osd_string = "AML_MBOX"; /* Max Chars: 14    */
		cec_version = <5>;/*5:1.4;6:2.0*/
		port_num = <1>;
		output = <1>;
		cec_sel = <1>;/*1:use one ip, 2:use 2 ip*/
		ee_cec;
		arc_port_mask = <0x1>;
		interrupts = <GIC_SPI 180 IRQ_TYPE_EDGE_RISING>;
		interrupt-names = "hdmi_aocecb";
		pinctrl-names = "default","hdmitx_aocecb","cec_pin_sleep";
		pinctrl-0=<&eecec_b>;
		pinctrl-1=<&eecec_b>;
		pinctrl-2=<&eecec_b>;
		clocks = <&clkc CLKID_CECB_DUAL_CLKOUT>;
		clock-names = "cecb_clk";
		reg = <0x0 0xfe044000 0x0 0x2ff
		       0x0 0xfe010000 0x0 0xfff
		       0x0 0xfe000000 0x0 0xfff
		       0x0 0xfe004000 0x0 0x2000>;
		reg-names = "ao","periphs","clock","pad_reg";
		mbox-names = "mbox_cec";
		mboxes = <&mbox_fifo S7D_REE2AO_AOCEC>;
	};

	aml_dma {
		compatible = "amlogic,aml_txlx_dma";
		reg = <0x0 0xfe440400 0x0 0x48>;
		interrupts = <0 24 1>;

		aml_aes {
			compatible = "amlogic,aes_g12a_dma";
			dev_name = "aml_aes_dma";
			status = "okay";
			iv_swap = /bits/ 8 <0x0>;
		};

		aml_sha {
			compatible = "amlogic,sha_dma";
			dev_name = "aml_sha_dma";
			hw_ctx_sz = /bits/ 32 <0x28>;
			status = "okay";
		};

		aml_sha3 {
			compatible = "amlogic,sha3_dma";
			dev_name = "aml_sha3_dma";
			status = "okay";
		};

		aml_tdes {
			compatible = "amlogic,des_dma,tdes_dma";
			dev_name = "aml_tdes_dma";
			status = "okay";
		};

		crypto {
			compatible = "amlogic,crypto_s4d";
			dev_name = "aml_crypto_dev";
			status = "okay";
			thread = /bits/ 8 <0x5>;
			interrupts = <0 29 1>;
		};
	};

	rng {
		compatible = "amlogic,meson-rng";
		status = "okay";
		#address-cells = <2>;
		#size-cells = <2>;
		reg = <0x0 0xfe440788 0x0 0x0c>;
		quality = /bits/ 16 <1000>;
		version = <2>;
	};

	canvas: canvas{
		compatible = "amlogic, meson, canvas";
		status = "okay";
		reg = <0x0 0xfe036048 0x0 0x2000>;
	};

	codec_io: codec_io {
		compatible = "amlogic, meson-s7d, codec-io";
		status = "okay";
		#address-cells=<2>;
		#size-cells=<2>;
		ranges;
		reg =	<0x0 0xfe002000 0x0 0x2000>,
			<0x0 0xfe320000 0x0 0x10000>,
			<0x0 0x0 0x0 0x0>,
			<0x0 0x0 0x0 0x00>,
			<0x0 0xff000000 0x0 0x40000>,
			<0x0 0xfe036000 0x0 0x2000>,
			<0x0 0x0 0x0 0x0>;
		reg-names = "cbus",
			    "dosbus",
			    "hiubus",
			    "aobus",
			    "vcbus",
			    "dmcbus",
			    "efusebus";
	};

	amvenc_avc{
		compatible = "amlogic, amvenc_avc";
		dev_name = "amvenc_avc";
		status = "okay";
		clocks = <&clkc CLKID_HCODEC>;
		clock-names = "cts_hcodec_aclk";
		interrupts = <0 93 1>;
		interrupt-names = "mailbox_2";
		reset-names = "hcodec_rst";
		power-domains = <&pwrdm PDID_S7D_DOS_HCODEC>;
	};
	jpegenc{
		compatible = "amlogic, jpegenc";
		dev_name = "jpegenc";
		status = "okay";
		clocks = <&clkc CLKID_HCODEC>;
		power-domains = <&pwrdm PDID_S7D_DOS_HCODEC>;
		clock-names = "clk_jpeg_enc";
		interrupts = <0 93 1>;
		interrupt-names = "mailbox_2";
		//reset-names = "jpegenc_rst";
		//resets = <&reset RESET_BRG_HCODEC_PIPL0>;
	};

	vpu: vpu {
		compatible = "amlogic, vpu-s7d";
		status = "okay";
		reg =	<0x0 0xfe000000 0x0 0x100    /* clk */
			 0x0 0xfe00c000 0x0 0x70     /* pwrctrl */
			 0x0 0xff000000 0x0 0xf000>; /* vcbus */
		clocks = <&clkc CLKID_VAPB>,
			<&clkc CLKID_SYS_VPU_INTR>,
			<&clkc CLKID_VPU_0>,
			<&clkc CLKID_VPU_1>,
			<&clkc CLKID_VPU>;
		clock-names =	"vapb_clk",
				"vpu_intr_gate",
				"vpu_clk0",
				"vpu_clk1",
				"vpu_clk";
		clk_level = <8>;
		/* 0:25M  1: 100.0M    2: 166.7M    3: 200.0M    4: 250.0M */
		/* 5: 333.3M    6: 400.0M    7: 500.0M    8: 666.7M */
	};

	rdma {
		compatible = "amlogic, meson-sc2, rdma";
		status = "okay";
		interrupts = <GIC_SPI 215 IRQ_TYPE_EDGE_RISING>;
		interrupt-names = "rdma";
		/* after sc2 */
		reset-names = "rdma";
		resets = <&reset RESET_RDMA>;
	};

	multi-di {
		compatible = "amlogic, dim-s7d";
		status = "okay";
		/* 0:use reserved; 1:use cma; 2:use cma as reserved */
		flag_cma = <4>;	//<1>;
		//memory-region = <&di_reserved>;
		//memory-region = <&di_cma_reserved>;
		interrupts = <0 203 1
				0 202 1>;
		interrupt-names = "pre_irq", "post_irq";
		clocks = <&clkc CLKID_VPU_CLKB>,
			<&clkc CLKID_VPU>;
		clock-names = "vpu_clkb",
			"vpu_mux";
		clock-range = <334 667>;
		/* buffer-size = <3621952>;(yuv422 8bit) */
		buffer-size = <4074560>;/*yuv422 fullpack*/
		/* reserve-iomap = "true"; */
		/* if enable nr10bit, set nr10bit-support to 1 */
		post-wr-support = <1>;
		nr10bit-support = <1>;
		nrds-enable = <1>;
	};

	vclk_serve: vclk_serve {
		compatible = "amlogic, vclk_serve";
		status = "okay";
		reg = <0x0 0xfe008000 0x0 0x300    /* ana reg */
			0x0 0xfe000000 0x0 0xc00>; /* clk reg */
	};

	vdac {
		compatible = "amlogic, vdac-s7D";
		status = "okay";
	};

	vout: vout {
		compatible = "amlogic, vout";
		status = "okay";

		/* fr_policy:
		 *    0: disable
		 *    1: nearby (only for 60->59.94 and 30->29.97)
		 *    2: force (60/50/30/24/59.94/23.97)
		 */
		fr_policy = <2>;
	};

	vout_mux: vout_mux {
		compatible = "amlogic, vout_mux";
		status = "okay";
	};

	dummy_venc: dummy_venc {
		compatible = "amlogic, dummy_venc_s1a";
		status = "okay";

		ports {
			port {
				#address-cells = <1>;
				#size-cells = <0>;
				dummyl_to_drm: endpoint@0 {
					reg = <0>;
					remote-endpoint = <0>;
				};
			};
		};
	};

	adc: adc {
		compatible = "amlogic, adc-s4d";
		status = "disabled";
		reg = <0x0 0xff654000 0x0 0x2000/* afe reg base */
			0x0 0xfe008000 0x0 0x2000/* hiu base */
			>;
	};

	ir: ir@8000 {
		compatible = "amlogic, meson-ir";
		reg = <0x0 0xfe084080 0x0 0xA4>,
			<0x0 0xfe084000 0x0 0x58>;
		status = "disable";
		protocol = <REMOTE_TYPE_NEC>;
		interrupts = <GIC_SPI 148 IRQ_TYPE_EDGE_RISING>;
		map = <&custom_maps>;
		max_frame_time = <200>;
	};

	p_tsensor: p_tsensor@fe020000 {
		compatible = "amlogic, r1p1-tsensor";
		status = "okay";
		reg = <0x0 0xfe020000 0x0 0x50>;
		tsensor_id = <1>;
		cal_type = <0x11>;
		cal_coeff = <270 370 2747 9164>;
		rtemp = <110000>;
		interrupts = <GIC_SPI 30 IRQ_TYPE_LEVEL_HIGH>;
		clocks = <&clkc CLKID_TS>;
		clock-names = "ts_comp";
		#thermal-sensor-cells = <1>;
	};

	dmc_tsensor: dmc_tsensor {
		compatible = "amlogic, indmc-tsensor";
		status = "okay";
		#thermal-sensor-cells = <1>;
		#cooling-cells = <2>;
		tsensor_id = <2>;
		reg_dram_type = <0xfe036814>;
		reg_dram_rate = <0xfe0368a8>;
		reg_sensor = <0xfe036a80>;
		reg_dmc_refresh = <0xfe0364b4 0xfe0365b4>;
		reg_dmc_init = <0xfe036678 0xfe036674>;
		sensor_bits_need_reverse;
	};

	meson_cooldev: meson-cooldev@0 {
			status = "okay";
			compatible = "amlogic, meson-cooldev";
			cooling_devices {
				cpucore_cool_cluster0 {
					cluster_id = <0>;
					node_name = "cpucore_cool0";
					device_type = "cpucore";
				};
				gpufreq_cool {
					dyn_coeff = <140>;
					node_name = "valhall";
					device_type = "gpufreq";
				};
			};
			cpucore_cool0:cpucore_cool0 {
				#cooling-cells = <2>; /* min followed by max */
			};
		};/*meson cooling devices end*/

	thermal-zones {
		soc_thermal: soc_thermal {
			polling-delay = <1000>;
			polling-delay-passive = <100>;
			sustainable-power = <1160>;
			thermal-sensors = <&p_tsensor 0>;
			trips {
				pswitch_on: trip-point@0 {
					temperature = <85000>;
					hysteresis = <5000>;
					type = "passive";
				};
				pcontrol: trip-point@1 {
					temperature = <95000>;
					hysteresis = <5000>;
					type = "passive";
				};
				pcritical: trip-point@2 {
					temperature = <105000>;
					hysteresis = <1000>;
					type = "critical";
				};
			};

			cooling-maps {
				cpufreq_cooling_map {
					trip = <&pcontrol>;
					cooling-device = <&CPU0 0 8>;
					contribution = <1024>;
				};
				gpufreq_cooling_map {
					trip = <&pcontrol>;
					cooling-device = <&gpu 0 3>;
					contribution = <1024>;
				};
			};
		};

		dmc_thermal: dmc_thermal {
			polling-delay = <500>;
			polling-delay-passive = <500>;
			thermal-sensors = <&dmc_tsensor 2>;
			trips {
				dmc_hot: trip-point@0 {
					temperature = <15000>;
					hysteresis = <5000>;
					type = "hot";
				};
			};

			cooling-maps {
				dmc_cooling_map {
					trip = <&dmc_hot>;
					cooling-device = <&dmc_tsensor 0 0>;
					contribution = <1024>;
				};
			};
		};
	};/*thermal zone end*/

	ion_dev {
		compatible = "amlogic, ion_dev";
		memory-region = <&ion_cma_reserved
				&ion_fb_reserved>;
	};

	gpu_protected_memory_allocator: protected-memory-allocator {
		compatible = "arm,protected-memory-allocator";
		memory-region = <&mali_protected>;
	};

	meson_uvm {
		compatible = "amlogic, meson_uvm";
		status = "okay";
	};

	meson_videotunnel{
		compatible = "amlogic, meson_videotunnel";
		status = "okay";
	};

	fb: fb {
		compatible = "amlogic, fb-s7d";
		memory-region = <&logo_reserved>;
		status = "disabled";
		interrupts = <GIC_SPI 197 IRQ_TYPE_EDGE_RISING
			GIC_SPI 215 IRQ_TYPE_EDGE_RISING>;
		interrupt-names = "viu-vsync", "rdma";
		/* uboot logo,fb0/fb1 memory size,if afbcd fb0=0x01851000*/
		display_mode_default = "1080p60hz";
		scale_mode = <1>;
		/** 0:VPU free scale 1:OSD free scale 2:OSD super scale */
		display_size_default = <1920 1080 1920 2160 32>;
		/*1920*1080*4*3 = 0x17BB000*/
	};

	irblaster: meson-irblaster@fe08410c {
		compatible = "amlogic, meson_irblaster";
		status = "disabled";
		reg = <0x0 0xfe08414C 0x0 0x10>;
		#irblaster-cells = <2>;
		interrupts = <GIC_SPI 149 IRQ_TYPE_EDGE_RISING>;
		pinctrl-names = "default";
		pinctrl-0 = <&irblaster_pins>;
	};

	/*if you want to use vdin just modify status to "ok"*/
	vdin0: vdin0 {
		compatible = "amlogic, vdin-s7d";
		dev_name = "vdin0";
		status = "disabled";
		reserve-iomap = "true";
		flag_cma = <0>;/*1:share with codec_mm;2:cma alone*/
		/*MByte, if 10bit disable: 64M(YUV422),
		 *if 10bit enable: 64*1.5 = 96M(YUV422)
		 *if support 4K2K-YUV444-10bit-WR:3840*2160*4*4 ~= 128M
		 *if support 4K2K-YUV422-10bit-wr:3840*2160*3*4 ~= 96M
		 *if support 4K2K-YUV422-8BIT-WR:3840*2160*2*4 ~= 64M
		 *if support 1080p-YUV422-8BIT-WR:1920*1080*2*4 ~= 16M
		 */
		/*cma_size = <16>;*/
		interrupts = <0 210 1>;
		rdma-irq = <2>;
		//clocks = <&clkc CLKID_FCLK_DIV5>, <&clkc CLKID_VDIN_MEAS_GATE>;
		//clock-names = "fclk_div5", "cts_vdin_meas_clk";
		vdin_id = <0>;
		/* vdin v4l2 */
		v4l_support_en = <0>;
		v4l_vd_num = <70>;
		/* v4l2 capability */
		driver   = "vdin_video";
		card     = "meson-s4d";
		bus_info = "vdin0 v4l2";
		version  = <0x20220120>;
		/* fe_ports refer to tvin.h */
		fe_ports = <0x00001001   /* CVBS1 */
			0x00004000   /* HDMI0 */
			0x00004001   /* HDMI1 */
			0x00004002>; /* HDMI2 */
		/* vdin v4l2 end */
	};
	vdin1: vdin1 {
		compatible = "amlogic, vdin-s7d";
		dev_name = "vdin1";
		status = "okay";
		reserve-iomap = "true";
		flag_cma = <0>;/*1:share with codec_mm;0:cma alone*/
		interrupts = <0 212 1>;
		rdma-irq = <4>;
		vdin_id = <1>;
		/* vdin v4l2 */
		v4l_support_en = <0>;
		v4l_vd_num = <71>;
		/* v4l2 capability */
		driver   = "vdin_video";
		card     = "meson-s4d";
		bus_info = "vdin1 v4l2";
		version  = <0x20220120>;
		/* fe_ports refer to tvin.h */
		fe_ports = <0x0000a002   /* WB0_VD1 */
			0x0000a003   /* WB0_VD2 */
			0x0000a004   /* WB0_OSD1 */
			0x0000a005   /* WB0_OSD2 */
			0x0000a006   /* WB0_VPP */
			0x0000a007   /* WB0_VDIN_BIST */
			0x0000a008>; /* WB0_POST_BLEND */
		/* vdin v4l2 end */
	};

	meson-amvideom {
		compatible = "amlogic, amvideom-s7d";
		dev_name = "amvideom";
		status = "okay";
		interrupts = <GIC_SPI 197 IRQ_TYPE_EDGE_RISING>;
		interrupt-names = "vsync";
	};

	lut_dma:lut_dma {
		compatible = "amlogic, meson-s5, lut_dma";
		status = "okay";
	};

	video_composer {
		compatible = "amlogic, video_composer";
		dev_name = "video_composer";
		status = "okay";
	};

	di_process {
		compatible = "amlogic, di_process";
		dev_name = "di_process";
		status = "okay";
	};

	vpu_security {
		compatible = "amlogic, meson-s7, vpu_security";
		dev_name = "amlogic-vpu-security";
		status = "okay";
		interrupts = <GIC_SPI 220 IRQ_TYPE_EDGE_RISING>;
		interrupt-names = "vpu_security";
	};

	dmx_aucpu: aucpu {
		compatible = "amlogic, aucpu";
		dev_name = "aml_aucpu";
		status = "okay";
		interrupts = <0 77 1>;
		interrupt-names = "aucpu_irq";
		reg = <0x0 0xfe09e080 0x0 0x100>;
	};

	ge2d {
		compatible = "amlogic, ge2d-s7d";
		status = "okay";
		interrupts = <GIC_SPI 217 IRQ_TYPE_EDGE_RISING>;
		interrupt-names = "ge2d";
		clocks = <&clkc CLKID_VAPB>,
			<&clkc CLKID_GE2D>;
		clock-names = "clk_vapb_0",
			"clk_ge2d_gate";
		reg = <0x0 0xff040000 0x0 0x100>;
		power-domains = <&pwrdm PDID_S7D_GE2D>;
	};

	aml_bt: aml_bt {
		compatible = "amlogic, aml-bt";
		status = "disabled";
	};

	aml_wifi: aml_wifi {
		compatible = "amlogic, aml-wifi";
		status = "disabled";
		irq_trigger_type = "IRQF_TRIGGER_LOW";
		wifi_static_buf = <0>;
		//pinctrl-0 = <&pwm_e_pins>;
		//pinctrl-names = "default";
		pwm_config = <&wifi_pwm_conf>;
	};

	wifi_pwm_conf:wifi_pwm_conf{
		pwm_channel1_conf {
			pwms = <&pwm_e 0 30541 0>;
			duty-cycle = <15270>;
			times = <7>;
		};
		pwm_channel2_conf {
			pwms = <&pwm_e 2 30500 0>;
			duty-cycle = <15250>;
			times = <10>;
		};
	};

	state_led: state_led {
		compatible = "amlogic,state-led-aocpu";
		mboxes = <&mbox_fifo S7D_REE2AO_LED>;
		status = "disabled";
	};

	efusecheck: efusecheck{
		maincmd = <0x8200003E>;
		checknum = <3>;
		check0 = <&check_0>;
		check1 = <&check_1>;
		check2 = <&check_2>;
		check_0:check_0{
			checkname = "dgpk1";
			subcmd = <0x1000>;
		};
		check_1:check_1{
			checkname = "dgpk2";
			subcmd = <0x1001>;
		};
		check_2:check_2{
			checkname = "aud_id";
			subcmd = <0x1002>;
		};
	};
	efuse: efuse{
		compatible = "amlogic, efuse";
		reg=<0x0 0xfe440040 0x0 0x4>;
		secureboot_mask = <0x00000c00>;
		mem_size = <0x100000>;
		read_cmd = <0x82000030>;
		write_cmd = <0x82000031>;
		get_max_cmd = <0x82000033>;
		mem_in_base_cmd = <0x82000020>;
		mem_out_base_cmd = <0x82000021>;
		efuse_pattern_size = <0x600>;
		efuse_obj_cmd_status = <0x1>;
		key = <&efusekey>;
		check = <&efusecheck>;
		clock-names = "efuse_clk";
		status = "okay";
	};

	efusekey:efusekey{
		keynum = <4>;
		key0 = <&key_0>;
		key1 = <&key_1>;
		key2 = <&key_2>;
		key3 = <&key_3>;
		key_0:key_0{
			keyname = "mac";
			offset = <0>;
			size = <6>;
		};
		key_1:key_1{
			keyname = "mac_bt";
			offset = <6>;
			size = <6>;
		};
		key_2:key_2{
			keyname = "mac_wifi";
			offset = <12>;
			size = <6>;
		};
		key_3:key_3{
			keyname = "usid";
			offset = <18>;
			size = <16>;
		};
	};

	aml_mkl {
		compatible = "amlogic,aml_mkl";
		reg = <0x0 0xfe440200 0x0 0xf0>;
		kl_type = <1>;
		kl_vid_type = <1>;
		kl_offset = <0x80 0x88 0x8c 0x90>;
		status = "okay";
	};

	aml_kt {
		compatible = "amlogic,aml_kt";
		reg = <0x0 0xfe440500 0x0 0xa0>;
		kt_offset = <0x80 0x88 0x8c 0x90 0x94 0x98 0x9c>;
		kt_cap = <0x2407 0x6bf 0 64 0 32>;
		kt_reserved = <0>;
		status = "okay";
	};

	chosen {
		bootargs = "usbcore.autosuspend=-1";
	};

	gpu_opp_table: gpu_opp_table {
		compatible = "operating-points-v2";
		opp-285 {
			opp-hz = /bits/ 64 <285714281>;
			opp-microvolt = <1150>;
		};
		opp-400 {
			opp-hz = /bits/ 64 <400000000>;
			opp-microvolt = <1150>;
		};
		opp-500 {
			opp-hz = /bits/ 64 <500000000>;
			opp-microvolt = <1150>;
		};
		opp-800 {
			opp-hz = /bits/ 64 <800000000>;
			opp-microvolt = <1150>;
		};
	};
};

&periphs_pinctrl {
	i2c0_pins1:i2c0_pins1 {
		mux {
			groups = "i2cm_a_sda",
				"i2cm_a_scl";
			function = "i2cm_a";
			drive-strength = <3>;
			bias-disable;
		};
	};

	i2c0_pins1:i2c0_pins1 {
		mux {
			groups = "i2cm_a_sda_cc1",
				"i2cm_a_scl_cc2";
			function = "i2cm_a";
			drive-strength = <3>;
			bias-disable;
		};
	};

	i2c1_pins1:i2c1_pins1 {
		mux {
			groups = "i2cm_b_sda_c6",
				"i2cm_b_scl_c7";
			function = "i2cm_b";
			drive-strength = <3>;
			bias-disable;
		};
	};

	i2c1_pins2:i2c1_pins2 {
		mux {
			groups = "i2cm_b_sda_dv1",
				"i2cm_b_scl_dv2";
			function = "i2cm_b";
			drive-strength = <3>;
			bias-disable;
		};
	};

	i2c1_pins3:i2c1_pins3 {
		mux {
			groups = "i2cm_b_sda_h6",
				"i2cm_b_scl_h7";
			function = "i2cm_b";
			drive-strength = <3>;
			bias-disable;
		};
	};

	i2c1_pins4:i2c1_pins4 {
		mux {
			groups = "i2cm_b_sda_x17",
				"i2cm_b_scl_x18";
			function = "i2cm_b";
			drive-strength = <3>;
			bias-disable;
		};
	};

	i2c2_pins1:i2c2_pins1 {
		mux {
			groups = "i2cm_c_sda_dv5",
				"i2cm_c_scl_dv6";
			function = "i2cm_c";
			drive-strength = <3>;
			bias-disable;
		};
	};

	i2c2_pins2:i2c2_pins2 {
		mux {
			groups = "i2cm_c_sda_h0",
				"i2cm_c_scl_h1";
			function = "i2cm_c";
			drive-strength = <3>;
			bias-disable;
		};
	};

	i2c2_pins3:i2c2_pins3 {
		mux {
			groups = "i2cm_c_sda_h8",
				"i2cm_c_scl_h9";
			function = "i2cm_c";
			drive-strength = <3>;
			bias-disable;
		};
	};

	i2c3_pins1:i2c3_pins1 {
		mux {
			groups = "i2cm_d_sda_x10",
				"i2cm_d_scl_x11";
			function = "i2cm_d";
			drive-strength = <3>;
			bias-disable;
		};
	};

	i2c3_pins2:i2c3_pins2 {
		mux {
			groups = "i2cm_d_sda_z8",
				"i2cm_d_scl_z9";
			function = "i2cm_d";
			drive-strength = <3>;
			bias-disable;
		};
	};

	i2c4_pins1:i2c4_pins1 {
		mux {
			groups = "i2cm_e_scl_c2",
				"i2cm_e_sda_c3";
			function = "i2cm_e";
			drive-strength = <3>;
			bias-disable;
		};
	};

	i2c4_pins2:i2c4_pins2 {
		mux {
			groups = "i2cm_e_scl_d2",
				"i2cm_e_sda_d3";
			function = "i2cm_e";
			drive-strength = <3>;
			bias-disable;
		};
	};

	i2c4_pins3:i2c4_pins3 {
		mux {
			groups = "i2cm_e_scl_z11",
				"i2cm_e_sda_z12";
			function = "i2cm_e";
			drive-strength = <3>;
			bias-disable;
		};
	};

	a_uart_pins:a_uart {
		mux {
			groups = "uart_a_tx",
				"uart_a_rx",
				"uart_a_cts",
				"uart_a_rts";
			function = "uart_a";
			drive-strength-microamp = <3000>;
			bias-pull-up;
		};
	};

	c_uart_pins:c_uart {
		mux {
			groups = "uart_c_tx",
				"uart_c_rx";
			function = "uart_c";
			drive-strength-microamp = <3000>;
			bias-pull-up;
		};
	};

	d_uart_pins1:d_uart1 {
		mux {
			groups = "uart_d_tx_h4",
				"uart_d_rx_h5";
			function = "uart_d";
			drive-strength-microamp = <3000>;
			bias-pull-up;
		};
	};

	d_uart_pins2:d_uart2 {
		mux {
			groups = "uart_d_tx_z0",
				"uart_d_rx_z1";
			function = "uart_d";
			drive-strength-microamp = <3000>;
			bias-pull-up;
		};
	};

	e_uart_pins1:e_uart1 {
		mux {
			groups = "uart_e_tx_h10",
				"uart_e_rx_h11";
			function = "uart_e";
			drive-strength-microamp = <3000>;
			bias-pull-up;
		};
	};

	e_uart_pins2:e_uart2 {
		mux {
			groups = "uart_e_tx_z11",
				"uart_e_rx_z12";
			function = "uart_e";
			drive-strength-microamp = <3000>;
			bias-pull-up;
		};
	};

	e_uart_pins3:e_uart3 {
		mux {
			groups = "uart_e_tx_z8",
				"uart_e_rx_z9";
			function = "uart_e";
			drive-strength-microamp = <3000>;
			bias-pull-up;
		};
	};

	emmc_pins: emmc_pins {
		mux-0 {
			groups = "emmc_d0",
				 "emmc_d1",
				 "emmc_d2",
				 "emmc_d3",
				 "emmc_d4",
				 "emmc_d5",
				 "emmc_d6",
				 "emmc_d7",
				 "emmc_cmd";
			function = "emmc";
			bias-pull-up;
			drive-strength-microamp = <4000>;
		};

		mux-1 {
			groups = "emmc_clk";
			function = "emmc";
			bias-pull-up;
			drive-strength-microamp = <4000>;
		};
	};

	emmc_ds_pins: emmc_ds_pins {
		mux {
			groups = "emmc_ds";
			function = "emmc";
			bias-pull-down;
			drive-strength-microamp = <4000>;
		};
	};

	emmc_clk_gate_pins: emmc_clk_gate_pins {
		mux {
			groups = "GPIOB_8";
			function = "gpio_periphs";
			bias-pull-down;
			drive-strength-microamp = <4000>;
		};
	};

	all_nand_pins: all_nand_pins {
	mux {
			groups = "emmc_nand_d0",
				"emmc_nand_d1",
				"emmc_nand_d2",
				"emmc_nand_d3",
				"emmc_nand_d4",
				"emmc_nand_d5",
				"emmc_nand_d6",
				"emmc_nand_d7",
				"nand_ce0",
				"nand_ale",
				"nand_cle",
				"nand_wen_clk",
				"nand_ren_wr";
			function = "nand";
			input-enable;
		};
	};

	nand_cs_pins: nand_cs {
		mux {
			groups = "nand_ce0";
			function = "nand";
		};
	};

	sd_to_ao_uart_clr_pins: sd_to_ao_uart_clr_pins {
		mux {
			groups = "GPIOD_0",
				   "GPIOD_1";
			function = "gpio_periphs";
		};
	};

	sdcard_pins: sdcard_pins {
		mux {
			groups = "sdcard_d0_c0",
				 "sdcard_d1_c1",
				 "sdcard_d2_c2",
				 "sdcard_d3_c3",
				 "sdcard_clk_c4",
				 "sdcard_cmd_c5";
			function = "sdcard";
			bias-pull-up;
			drive-strength-microamp = <4000>;
		};
	};

	ao_to_sd_uart_pins: ao_to_sd_uart_pins {
		mux {
			groups = "uart_b_tx_c",
				"uart_b_rx_c";
			function = "uart_b";
			bias-pull-up;
			input-enable;
		};
	};

	ao_uart_pins: ao_uart_pins {
		mux {
			groups = "uart_b_tx_d",
				"uart_b_rx_d";
			function = "uart_b";
			bias-pull-up;
			input-enable;
		};
	};

	sd_clr_all_pins: sd_clr_all_pins {
		mux {
			groups = "GPIOC_0",
				   "GPIOC_1",
				   "GPIOC_2",
				   "GPIOC_3",
				   "GPIOC_5";
			function = "gpio_periphs";
			output-high;
		};
		mux1 {
			groups = "GPIOC_4";
			function = "gpio_periphs";
			output-low;
		};
	};

	sd_clr_noall_pins: sd_clr_noall_pins {
		mux {
			groups = "GPIOC_0",
				   "GPIOC_1",
				   "GPIOC_4",
				   "GPIOC_5";
			function = "gpio_periphs";
			output-high;
		};
	};

	sd_1bit_pins: sd_1bit_pins {
		mux {
			groups = "sdcard_d0_c0",
				 "sdcard_clk_c4",
				 "sdcard_cmd_c5";
			function = "sdcard";
			bias-pull-up;
			drive-strength-microamp = <4000>;
		};
	};

	sdcard_clk_gate_pins: sdcard_clk_gate_pins {
		mux {
			groups = "GPIOC_4";
			function = "gpio_periphs";
			bias-pull-down;
			drive-strength-microamp = <4000>;
		};
	};

	sd_iso7816_pins:sd_iso7816_pins {
		mux {
			groups = "iso7816_clk_h8",
				"iso7816_data_h9";
			function = "iso7816";
			input-enable;
			bias-pull-down;
		};
	};

	sdio_pins: sdio_pins {
		mux {
			groups = "sdio_d0",
				 "sdio_d1",
				 "sdio_d2",
				 "sdio_d3",
				 "sdio_clk",
				 "sdio_cmd";
			function = "sdio";
			bias-pull-up;
			drive-strength-microamp = <3000>;
		};
	};

	sdio_clk_gate_pins: sdio_clk_gate_pins {
		mux {
			groups = "GPIOX_4";
			function = "gpio_periphs";
			bias-pull-down;
			drive-strength-microamp = <3000>;
		};
	};

	hdmitx_hpd: hdmitx_hpd {
		mux {
			groups = "hdmitx_hpd_in";
			function = "hdmitx";
			bias-disable;
		};
	};

	hdmitx_hpd_gpio: hdmitx_hpd_gpio {
		mux {
			groups = "GPIOH_1";
			function = "gpio_periphs";
			bias-disable;
		};
	};

	hdmitx_ddc: hdmitx_ddc {
		mux {
			groups = "hdmitx_sda",
				"hdmitx_scl";
			function = "hdmitx";
			bias-disable;
			drive-strength = <3>;
		};
	};

	dtvdemod_if_agc_pins: dtvdemod_if_agc_pins {
		mux {
			groups = "dtv_a_if_agc_z10";
			function = "dtv";
		};
	};

	dtvdemod_if_agc2_pins: dtvdemod_if_agc2_pins {
		mux {
			groups = "dtv_b_if_agc";
			function = "dtv";
		};
	};

	dtvdemod_rf_agc_pins: dtvdemod_rf_agc_pins {
		mux {
			groups = "dtv_a_rf_agc";
			function = "dtv";
		};
	};

	diseqc_out: diseqc_out {
		mux {
			groups = "diseqc_out";
			function = "diseqc_out";
			bias-pull-down;
		};
	};

	diseqc_in: diseqc_in {
		mux {
			groups = "diseqc_in";
			function = "diseqc_in";
			bias-pull-down;
		};
	};

	eecec_a: ee_ceca {
		mux {
			groups = "ao_cec_a";
			function = "ao_cec_a";
		};
	};

	eecec_b: ee_cecb {
		mux {
			groups = "ao_cec_b";
			function = "ao_cec_b";
		};
	};

	jtag_a_pins: jtag_a_pin {
		mux {
			groups = "jtag_tdi",
				 "jtag_tdo",
				 "jtag_clk",
				 "jtag_tms";
			function = "jtag";
		};
	};

	jtag_b_pins: jtag_b_pin {
		mux {
			groups = "jtag2_tdi",
				 "jtag2_tdo",
				 "jtag2_clk",
				 "jtag2_tms";
			function = "jtag2";
		};
	};

	pwm_a_pins: pwm_a_pins {
		mux {
			groups = "pwm_a_d";
			function = "pwm_a";
		};
	};

	pwm_b_pins1: pwm_b_pins1 {
		mux {
			groups = "pwm_b_d";
			function = "pwm_b";
		};
	};

	pwm_b_pins2: pwm_b_pins2 {
		mux {
			groups = "pwm_b_x";
			function = "pwm_b";
		};
	};

	pwm_c_pins1: pwm_c_pins1 {
		mux {
			groups = "pwm_c_d";
			function = "pwm_c";
		};
	};

	pwm_c_pins2: pwm_c_pins2 {
		mux {
			groups = "pwm_c_x";
			function = "pwm_c";
		};
	};

	pwm_d_pins1: pwm_d_pins1 {
		mux {
			groups = "pwm_d_d";
			function = "pwm_d";
		};
	};

	pwm_d_pins2: pwm_d_pins2 {
		mux {
			groups = "pwm_d_h";
			function = "pwm_d";
		};
	};

	pwm_e_pins1: pwm_e_pins1 {
		mux {
			groups = "pwm_e_x16";
			function = "pwm_e";
		};
	};

	pwm_e_pins2: pwm_e_pins2 {
		mux {
			groups = "pwm_e_z";
			function = "pwm_e";
		};
	};

	pwm_f_pins1: pwm_f_pins1 {
		mux {
			groups = "pwm_f_x";
			function = "pwm_f";
		};
	};

	pwm_f_pins2: pwm_f_pins2 {
		mux {
			groups = "pwm_f_z";
			function = "pwm_f";
		};
	};

	pwm_g_pins1: pwm_g_pins1 {
		mux {
			groups = "pwm_g_d";
			function = "pwm_g";
		};
	};

	pwm_g_pins2: pwm_g_pins2 {
		mux {
			groups = "pwm_g_z";
			function = "pwm_g";
		};
	};

	pwm_h_pins: pwm_h_pins {
		mux {
			groups = "pwm_h";
			function = "pwm_h";
		};
	};

	pwm_i_pins1: pwm_i_pins1 {
		mux {
			groups = "pwm_i_d";
			function = "pwm_i";
		};
	};

	pwm_i_pins2: pwm_i_pins2 {
		mux {
			groups = "pwm_i_h";
			function = "pwm_i";
		};
	};

	pwm_j_pins: pwm_j_pins {
		mux {
			groups = "pwm_j";
			function = "pwm_j";
		};
	};

	pwm_a_hiz_pins: pwm_a_hiz_pins {
		mux {
			groups = "pwm_a_hiz";
			function = "pwm_a_hiz";
		};
	};

	pwm_b_hiz_pins: pwm_b_hiz_pins {
		mux {
			groups = "pwm_b_hiz";
			function = "pwm_b_hiz";
		};
	};

	pwm_c_hiz_pins: pwm_c_hiz_pins {
		mux {
			groups = "pwm_c_hiz";
			function = "pwm_b_hiz";
		};
	};

	pwm_g_hiz_pins: pwm_g_hiz_pins {
		mux {
			groups = "pwm_g_hiz";
			function = "pwm_g_hiz";
		};
	};

	remote_pins: remote_pin {
		mux {
			groups = "ir_remote_input";
			function = "ir_remote";
			bias-disable;
		};
	};

	irblaster_pins: irblaster_pins {
		mux {
			groups = "ir_remote_out";
			function = "ir_remote";
		};
	};

	spicc0_pins_x: spicc0_pins_x {
		mux {
			groups = "spi_a_mosi_x8",
				 "spi_a_miso_x9",
				 "spi_a_ss0_x10",
				 "spi_a_clk_x11";
			function = "spi_a";
		};
	};

	spicc0_pins_h: spicc0_pins_h {
		mux {
			groups = "spi_a_mosi_h5",
				 "spi_a_miso_h4",
				 "spi_a_ss0_h7",
				 "spi_a_clk_h6";
			function = "spi_a";
		};
	};

	spicc0_pins_z: spicc0_pins_z {
		mux {
			groups = "spi_a_mosi_z1",
				 "spi_a_miso_z0",
				 "spi_a_ss0_z3",
				 "spi_a_clk_z2";
			function = "spi_a";
		};
	};

	spifc_pins:spifc_pins {
		mux {
			groups = "spif_hold",
				 "spif_mo",
				 "spif_mi",
				 "spif_clk",
				 "spif_wp",
				 "spif_cs";
			function = "spif";
			drive-strength-microamp = <3000>;
		};
	};

	spdifin: spdifin {
		mux {/* GPIOH_5 */
			groups = "spdif_in";
			function = "spdif_in";
		};
	};

	eth_pins: eth {
		mux {
			groups = "eth_mdio",
				 "eth_mdc",
				 "eth_rgmii_rx_clk",
				 "eth_rx_dv",
				 "eth_rxd0",
				 "eth_rxd1",
				 "eth_txen",
				 "eth_txd0",
				 "eth_txd1";
			function = "eth";
			drive-strength-microamp = <4000>;
			bias-disable;
		};
	};

	eth_rgmii_pins: eth-rgmii {
		mux {
			groups = "eth_rxd2_rgmii",
				 "eth_rxd3_rgmii",
				 "eth_rgmii_tx_clk",
				 "eth_txd2_rgmii",
				 "eth_txd3_rgmii";
			function = "eth";
			drive-strength-microamp = <4000>;
			bias-disable;
		};
	};
};

&gpu{
	status = "okay";
	operating-points-v2 = <&gpu_opp_table>; /* s7d use devfreq policy*/
	reg =   <0x0 0xFD000000 0x0 0x800000>, /*mali APB bus base address*/
		<0x0 0xFE002000 0x0 0x01000>, /*reset register*/
		<0x0 0xFE000000 0x0 0x01000>; /*aobus TODO update*/

	interrupts = <GIC_SPI 144 IRQ_TYPE_LEVEL_HIGH>,
		     <GIC_SPI 145 IRQ_TYPE_LEVEL_HIGH>,
		     <GIC_SPI 146 IRQ_TYPE_LEVEL_HIGH>;
	interrupt-names = "GPU", "MMU", "JOB";

	/* Protected memory allocator default not available*/
	//protected-memory-allocator = <&gpu_protected_memory_allocator>;

	num_of_pp = <1>;
	system-coherency = <31>;
	clocks = <&clkc CLKID_MALI>,
		 <&clkc CLKID_MALI_STACK>;
	clock-names = "gpu_mux", "gpu_stack";

	/*
	 * Mali clocking is provided by two identical clock paths
	 * MALI_0 and MALI_1 muxed to a single clock by a glitch
	 * free mux to safely change frequency while running.
	 */
	assigned-clocks = <&clkc CLKID_MALI_0_SEL>,
			  <&clkc CLKID_MALI_0>,
			  <&clkc CLKID_MALI>,
			  <&clkc CLKID_MALI_STACK_0_SEL>,
			  <&clkc CLKID_MALI_STACK_0>,
			  <&clkc CLKID_MALI_STACK>; /* Glitch free mux */
	assigned-clock-parents = <&clkc CLKID_FCLK_DIV5>,
				 <0>, /* Do Nothing */
				 <&clkc CLKID_MALI_0>,
				 <&clkc CLKID_FCLK_DIV5>,
				 <0>,
				 <&clkc CLKID_MALI_STACK_0>;
	assigned-clock-rates = <0>, /* Do Nothing */
			       <400000000>,
			       <0>,
			       <0>,
			       <400000000>,
			       <0>; /* Do Nothing */

	//tbl = <&dvfs400_cfg>;//bringup s7d use fix clock 400M
};

#include "mesons7d_cpufreq.dtsi"
